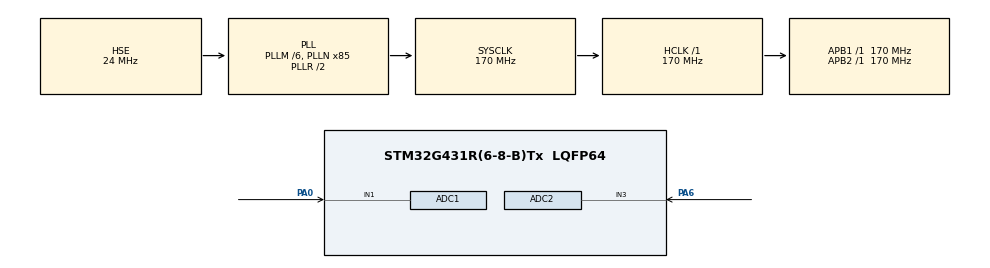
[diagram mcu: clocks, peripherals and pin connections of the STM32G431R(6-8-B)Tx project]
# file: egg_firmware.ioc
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ADC1.Channel-0\#ChannelRegularConversion=ADC_CHANNEL_1
ADC1.ContinuousConvMode=ENABLE
ADC1.DMAAccessModeView=ENABLE
ADC1.DMAContinuousRequests=DISABLE
ADC1.EOCSelection=ADC_EOC_SINGLE_CONV
ADC1.ExternalTrigConv=ADC_EXTERNALTRIG_T1_TRGO
ADC1.Mode=ADC_DUALMODE_REGSIMULT
ADC1.NbrOfConversion=1
ADC1.NbrOfConversionFlag=1
ADC1.OffsetNumber-0\#ChannelRegularConversion=ADC_OFFSET_NONE
ADC1.Rank-0\#ChannelRegularConversion=1
ADC1.SamplingTime-0\#ChannelRegularConversion=ADC_SAMPLETIME_247CYCLES_5
ADC1.master=1
ADC2.Channel-1\#ChannelRegularConversion=ADC_CHANNEL_3
ADC2.DMAAccessModeView=ENABLE
ADC2.Mode=ADC_DUALMODE_REGSIMULT
ADC2.NbrOfConversionFlag=1
ADC2.OffsetNumber-1\#ChannelRegularConversion=ADC_OFFSET_NONE
ADC2.Rank-1\#ChannelRegularConversion=1
ADC2.SamplingTime-1\#ChannelRegularConversion=ADC_SAMPLETIME_2CYCLES_5
Dma.ADC1.0.Direction=DMA_PERIPH_TO_MEMORY
Dma.ADC1.0.EventEnable=DISABLE
Dma.ADC1.0.Instance=DMA1_Channel1
Dma.ADC1.0.MemDataAlignment=DMA_MDATAALIGN_HALFWORD
Dma.ADC1.0.MemInc=DMA_MINC_ENABLE
Dma.ADC1.0.Mode=DMA_CIRCULAR
Dma.ADC1.0.PeriphDataAlignment=DMA_PDATAALIGN_HALFWORD
Dma.ADC1.0.PeriphInc=DMA_PINC_DISABLE
Dma.ADC1.0.Polarity=HAL_DMAMUX_REQ_GEN_RISING
Dma.ADC1.0.Priority=DMA_PRIORITY_LOW
Dma.ADC1.0.RequestNumber=1
Dma.ADC1.0.SignalID=NONE
Dma.ADC1.0.SyncEnable=DISABLE
Dma.ADC1.0.SyncPolarity=HAL_DMAMUX_SYNC_NO_EVENT
Dma.ADC1.0.SyncRequestNumber=1
Dma.ADC1.0.SyncSignalID=NONE
Dma.Request0=ADC1
Mcu.Family=STM32G4
Mcu.Name=STM32G431R(6-8-B)Tx
Mcu.Package=LQFP64
NVIC.ADC1_2_IRQn=true\:0\:0\:false\:false\:true\:true\:true\:true
NVIC.DMA1_Channel1_IRQn=true\:0\:0\:false\:false\:true\:false\:true\:true
NVIC.PriorityGroup=NVIC_PRIORITYGROUP_4
NVIC.TIM1_TRG_COM_TIM17_IRQn=true\:15\:0\:false\:false\:true\:false\:true\:true
NVIC.TimeBase=TIM1_TRG_COM_TIM17_IRQn
NVIC.TimeBaseIP=TIM17
PA0.Mode=IN1-Single-Ended
PA0.Signal=ADC1_IN1
PA13.Mode=Serial_Wire
PA13.Signal=SYS_JTMS-SWDIO
PA14.Mode=Serial_Wire
PA14.Signal=SYS_JTCK-SWCLK
PA6.Mode=IN3-Single-Ended
PA6.Signal=ADC2_IN3
PF0-OSC_IN.Mode=HSE-External-Oscillator
PF0-OSC_IN.Signal=RCC_OSC_IN
PF1-OSC_OUT.Mode=HSE-External-Oscillator
PF1-OSC_OUT.Signal=RCC_OSC_OUT
ProjectManager.HeapSize=0x200
ProjectManager.StackSize=0x400
ProjectManager.TargetToolchain=STM32CubeIDE
RCC.ADC12Freq_Value=170000000
RCC.AHBFreq_Value=170000000
RCC.APB1Freq_Value=170000000
RCC.APB1TimFreq_Value=170000000
RCC.APB2Freq_Value=170000000
RCC.APB2TimFreq_Value=170000000
RCC.CortexFreq_Value=170000000
RCC.EXTERNAL_CLOCK_VALUE=12288000
RCC.HCLKFreq_Value=170000000
RCC.HSE_VALUE=24000000
RCC.HSI48_VALUE=48000000
RCC.HSI_VALUE=16000000
RCC.LSE_VALUE=32768
RCC.PLLM=RCC_PLLM_DIV6
RCC.PLLN=85
RCC.PLLSourceVirtual=RCC_PLLSOURCE_HSE
RCC.SYSCLKFreq_VALUE=170000000
RCC.SYSCLKSource=RCC_SYSCLKSOURCE_PLLCLK
RCC.USBFreq_Value=170000000
RCC.VCOOutputFreq_Value=340000000
TIM1.PeriodNoDither=10303-1
TIM1.Prescaler=5-1
TIM1.TIM_MasterOutputTrigger=TIM_TRGO_UPDATE
VP_SYS_VS_DBSignals.Mode=DisableDeadBatterySignals
VP_SYS_VS_tim17.Mode=TIM17
VP_TIM1_VS_ClockSourceINT.Mode=Internal
board=custom

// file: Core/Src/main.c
/* USER CODE BEGIN Header */
/**
  ******************************************************************************
  * @file           : main.c
  * @brief          : Main program body
  ******************************************************************************
  * @attention
  *
  * Copyright (c) 2025 STMicroelectronics.
  * All rights reserved.
  *
  * This software is licensed under terms that can be found in the LICENSE file
  * in the root directory of this software component.
  * If no LICENSE file comes with this software, it is provided AS-IS.
  *
  ******************************************************************************
  */
/* USER CODE END Header */
#include "main.h"

/* USER CODE BEGIN PD */
#define ADC_COUNT 2
#define ADC_RAW_TO_VOLTAGE 0.0008058608f
/* USER CODE END PD */

ADC_HandleTypeDef hadc1;
ADC_HandleTypeDef hadc2;
DMA_HandleTypeDef hdma_adc1;

TIM_HandleTypeDef htim1;

/* USER CODE BEGIN PV */
volatile uint16_t adc_data[ADC_COUNT];
volatile float voltage_data[ADC_COUNT];
/* USER CODE END PV */

void SystemClock_Config(void);
static void MX_GPIO_Init(void);
static void MX_DMA_Init(void);
static void MX_ADC1_Init(void);
static void MX_ADC2_Init(void);
static void MX_TIM1_Init(void);
/* USER CODE BEGIN PFP */

void HAL_ADC_ConvCpltCallback(ADC_HandleTypeDef *hadc)
{
	for(uint8_t i = 0; i < ADC_COUNT; i++)
	{
		voltage_data[i] = ADC_RAW_TO_VOLTAGE * (float)adc_data[i];
	}
}

/* USER CODE END PFP */

int main(void)
{

  /* USER CODE BEGIN 1 */
  static int i = 0;
  /* USER CODE END 1 */

  /* MCU Configuration--------------------------------------------------------*/

  /* Reset of all peripherals, Initializes the Flash interface and the Systick. */
  HAL_Init();

  /* Configure the system clock */
  SystemClock_Config();

  /* Initialize all configured peripherals */
  MX_GPIO_Init();
  MX_DMA_Init();
  MX_ADC1_Init();
  MX_ADC2_Init();
  MX_TIM1_Init();
  /* USER CODE BEGIN 2 */
  //HAL_ADCEx_Calibration_Start(&hadc1, ADC_SINGLE_ENDED);
  //HAL_ADCEx_Calibration_Start(&hadc2, ADC_SINGLE_ENDED);

  HAL_ADCEx_MultiModeStart_DMA(&hadc1, (uint32_t*) adc_data, ADC_COUNT);
  HAL_ADC_Start(&hadc2);

  HAL_TIM_Base_Start(&htim1);

  /* USER CODE END 2 */

  /* Infinite loop */
  while (1)
  {

    /* USER CODE BEGIN 3 */
	  i++;
  }
  /* USER CODE END 3 */
}

void SystemClock_Config(void)
{
  RCC_OscInitTypeDef RCC_OscInitStruct = {0};
  RCC_ClkInitTypeDef RCC_ClkInitStruct = {0};

  /** Configure the main internal regulator output voltage
  */
  HAL_PWREx_ControlVoltageScaling(PWR_REGULATOR_VOLTAGE_SCALE1_BOOST);

  /** Initializes the RCC Oscillators according to the specified parameters
  * in the RCC_OscInitTypeDef structure.
  */
  RCC_OscInitStruct.OscillatorType = RCC_OSCILLATORTYPE_HSE;
  RCC_OscInitStruct.HSEState = RCC_HSE_ON;
  RCC_OscInitStruct.PLL.PLLState = RCC_PLL_ON;
  RCC_OscInitStruct.PLL.PLLSource = RCC_PLLSOURCE_HSE;
  RCC_OscInitStruct.PLL.PLLM = RCC_PLLM_DIV6;
  RCC_OscInitStruct.PLL.PLLN = 85;
  RCC_OscInitStruct.PLL.PLLP = RCC_PLLP_DIV2;
  RCC_OscInitStruct.PLL.PLLQ = RCC_PLLQ_DIV2;
  RCC_OscInitStruct.PLL.PLLR = RCC_PLLR_DIV2;
  if (HAL_RCC_OscConfig(&RCC_OscInitStruct) != HAL_OK)
  {
    Error_Handler();
  }

  /** Initializes the CPU, AHB and APB buses clocks
  */
  RCC_ClkInitStruct.ClockType = RCC_CLOCKTYPE_HCLK|RCC_CLOCKTYPE_SYSCLK
                              |RCC_CLOCKTYPE_PCLK1|RCC_CLOCKTYPE_PCLK2;
  RCC_ClkInitStruct.SYSCLKSource = RCC_SYSCLKSOURCE_PLLCLK;
  RCC_ClkInitStruct.AHBCLKDivider = RCC_SYSCLK_DIV1;
  RCC_ClkInitStruct.APB1CLKDivider = RCC_HCLK_DIV1;
  RCC_ClkInitStruct.APB2CLKDivider = RCC_HCLK_DIV1;

  if (HAL_RCC_ClockConfig(&RCC_ClkInitStruct, FLASH_LATENCY_4) != HAL_OK)
  {
    Error_Handler();
  }
}

static void MX_ADC1_Init(void)
{

  ADC_MultiModeTypeDef multimode = {0};
  ADC_ChannelConfTypeDef sConfig = {0};

  /** Common config
  */
  hadc1.Instance = ADC1;
  hadc1.Init.ClockPrescaler = ADC_CLOCK_SYNC_PCLK_DIV4;
  hadc1.Init.Resolution = ADC_RESOLUTION_12B;
  hadc1.Init.DataAlign = ADC_DATAALIGN_RIGHT;
  hadc1.Init.GainCompensation = 0;
  hadc1.Init.ScanConvMode = ADC_SCAN_DISABLE;
  hadc1.Init.EOCSelection = ADC_EOC_SINGLE_CONV;
  hadc1.Init.LowPowerAutoWait = DISABLE;
  hadc1.Init.ContinuousConvMode = ENABLE;
  hadc1.Init.NbrOfConversion = 1;
  hadc1.Init.DiscontinuousConvMode = DISABLE;
  hadc1.Init.ExternalTrigConv = ADC_EXTERNALTRIG_T1_TRGO;
  hadc1.Init.ExternalTrigConvEdge = ADC_EXTERNALTRIGCONVEDGE_RISING;
  hadc1.Init.DMAContinuousRequests = DISABLE;
  hadc1.Init.Overrun = ADC_OVR_DATA_PRESERVED;
  hadc1.Init.OversamplingMode = DISABLE;
  if (HAL_ADC_Init(&hadc1) != HAL_OK)
  {
    Error_Handler();
  }

  /** Configure the ADC multi-mode
  */
  multimode.Mode = ADC_DUALMODE_REGSIMULT;
  multimode.DMAAccessMode = ADC_DMAACCESSMODE_12_10_BITS;
  multimode.TwoSamplingDelay = ADC_TWOSAMPLINGDELAY_1CYCLE;
  if (HAL_ADCEx_MultiModeConfigChannel(&hadc1, &multimode) != HAL_OK)
  {
    Error_Handler();
  }

  /** Configure Regular Channel
  */
  sConfig.Channel = ADC_CHANNEL_1;
  sConfig.Rank = ADC_REGULAR_RANK_1;
  sConfig.SamplingTime = ADC_SAMPLETIME_247CYCLES_5;
  sConfig.SingleDiff = ADC_SINGLE_ENDED;
  sConfig.OffsetNumber = ADC_OFFSET_NONE;
  sConfig.Offset = 0;
  if (HAL_ADC_ConfigChannel(&hadc1, &sConfig) != HAL_OK)
  {
    Error_Handler();
  }

}

static void MX_ADC2_Init(void)
{

  ADC_ChannelConfTypeDef sConfig = {0};

  /** Common config
  */
  hadc2.Instance = ADC2;
  hadc2.Init.ClockPrescaler = ADC_CLOCK_SYNC_PCLK_DIV4;
  hadc2.Init.Resolution = ADC_RESOLUTION_12B;
  hadc2.Init.DataAlign = ADC_DATAALIGN_RIGHT;
  hadc2.Init.GainCompensation = 0;
  hadc2.Init.ScanConvMode = ADC_SCAN_DISABLE;
  hadc2.Init.EOCSelection = ADC_EOC_SINGLE_CONV;
  hadc2.Init.LowPowerAutoWait = DISABLE;
  hadc2.Init.ContinuousConvMode = ENABLE;
  hadc2.Init.NbrOfConversion = 1;
  hadc2.Init.DiscontinuousConvMode = DISABLE;
  hadc2.Init.DMAContinuousRequests = DISABLE;
  hadc2.Init.Overrun = ADC_OVR_DATA_PRESERVED;
  hadc2.Init.OversamplingMode = DISABLE;
  if (HAL_ADC_Init(&hadc2) != HAL_OK)
  {
    Error_Handler();
  }

  /** Configure Regular Channel
  */
  sConfig.Channel = ADC_CHANNEL_3;
  sConfig.Rank = ADC_REGULAR_RANK_1;
  sConfig.SamplingTime = ADC_SAMPLETIME_2CYCLES_5;
  sConfig.SingleDiff = ADC_SINGLE_ENDED;
  sConfig.OffsetNumber = ADC_OFFSET_NONE;
  sConfig.Offset = 0;
  if (HAL_ADC_ConfigChannel(&hadc2, &sConfig) != HAL_OK)
  {
    Error_Handler();
  }

}

static void MX_TIM1_Init(void)
{

  TIM_ClockConfigTypeDef sClockSourceConfig = {0};
  TIM_MasterConfigTypeDef sMasterConfig = {0};

  htim1.Instance = TIM1;
  htim1.Init.Prescaler = 5-1;
  htim1.Init.CounterMode = TIM_COUNTERMODE_UP;
  htim1.Init.Period = 10302;
  htim1.Init.ClockDivision = TIM_CLOCKDIVISION_DIV1;
  htim1.Init.RepetitionCounter = 0;
  htim1.Init.AutoReloadPreload = TIM_AUTORELOAD_PRELOAD_DISABLE;
  if (HAL_TIM_Base_Init(&htim1) != HAL_OK)
  {
    Error_Handler();
  }
  sClockSourceConfig.ClockSource = TIM_CLOCKSOURCE_INTERNAL;
  if (HAL_TIM_ConfigClockSource(&htim1, &sClockSourceConfig) != HAL_OK)
  {
    Error_Handler();
  }
  sMasterConfig.MasterOutputTrigger = TIM_TRGO_UPDATE;
  sMasterConfig.MasterOutputTrigger2 = TIM_TRGO2_RESET;
  sMasterConfig.MasterSlaveMode = TIM_MASTERSLAVEMODE_DISABLE;
  if (HAL_TIMEx_MasterConfigSynchronization(&htim1, &sMasterConfig) != HAL_OK)
  {
    Error_Handler();
  }

}

static void MX_DMA_Init(void)
{

  /* DMA controller clock enable */
  __HAL_RCC_DMAMUX1_CLK_ENABLE();
  __HAL_RCC_DMA1_CLK_ENABLE();

  /* DMA interrupt init */
  /* DMA1_Channel1_IRQn interrupt configuration */
  HAL_NVIC_SetPriority(DMA1_Channel1_IRQn, 0, 0);
  HAL_NVIC_EnableIRQ(DMA1_Channel1_IRQn);

}

static void MX_GPIO_Init(void)
{

  /* GPIO Ports Clock Enable */
  __HAL_RCC_GPIOF_CLK_ENABLE();
  __HAL_RCC_GPIOA_CLK_ENABLE();

}

void HAL_TIM_PeriodElapsedCallback(TIM_HandleTypeDef *htim)
{
  if (htim->Instance == TIM17)
  {
    HAL_IncTick();
  }
}

void Error_Handler(void)
{
  __disable_irq();
  while (1)
  {
  }
}
